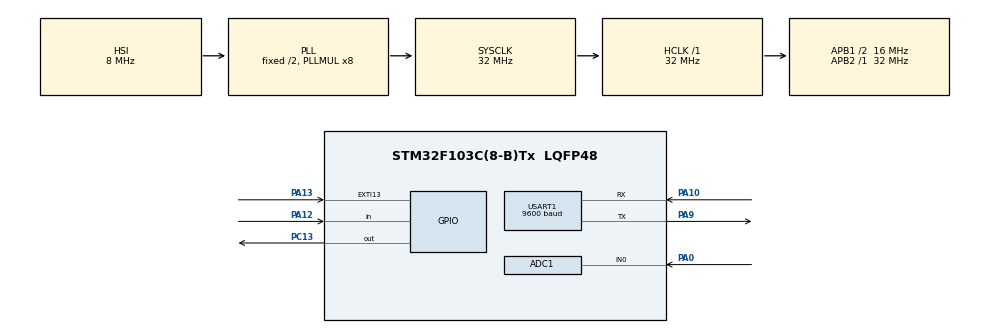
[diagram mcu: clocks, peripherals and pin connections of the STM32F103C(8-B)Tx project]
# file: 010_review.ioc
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ADC1.Channel-2\#ChannelRegularConversion=ADC_CHANNEL_0
ADC1.ContinuousConvMode=ENABLE
ADC1.NbrOfConversionFlag=1
ADC1.Rank-2\#ChannelRegularConversion=1
ADC1.SamplingTime-2\#ChannelRegularConversion=ADC_SAMPLETIME_1CYCLE_5
ADC1.master=1
Mcu.Family=STM32F1
Mcu.Name=STM32F103C(8-B)Tx
Mcu.Package=LQFP48
NVIC.EXTI15_10_IRQn=true\:0\:0\:false\:false\:true\:true\:true\:true
NVIC.PriorityGroup=NVIC_PRIORITYGROUP_4
NVIC.TIM2_IRQn=true\:0\:0\:false\:false\:true\:true\:true\:true
NVIC.USART1_IRQn=true\:0\:0\:false\:false\:true\:true\:true\:true
PA0-WKUP.Signal=ADCx_IN0
PA10.Mode=Asynchronous
PA10.Signal=USART1_RX
PA12.Signal=GPIO_Input
PA13.GPIO_ModeDefaultEXTI=GPIO_MODE_IT_FALLING
PA13.GPIO_PuPd=GPIO_PULLUP
PA13.Signal=GPXTI13
PA9.Mode=Asynchronous
PA9.Signal=USART1_TX
PC13-TAMPER-RTC.Signal=GPIO_Output
ProjectManager.HeapSize=0x200
ProjectManager.StackSize=0x400
ProjectManager.TargetToolchain=Makefile
RCC.ADCPresc=RCC_ADCPCLK2_DIV4
RCC.AHBFreq_Value=32000000
RCC.APB1CLKDivider=RCC_HCLK_DIV2
RCC.APB1Freq_Value=16000000
RCC.APB1TimFreq_Value=32000000
RCC.APB2Freq_Value=32000000
RCC.APB2TimFreq_Value=32000000
RCC.HCLKFreq_Value=32000000
RCC.PLLMUL=RCC_PLL_MUL8
RCC.SYSCLKFreq_VALUE=32000000
RCC.SYSCLKSource=RCC_SYSCLKSOURCE_PLLCLK
RCC.USBFreq_Value=32000000
SH.ADCx_IN0.0=ADC1_IN0,IN0
TIM2.Period=300
TIM2.Prescaler=31999
USART1.BaudRate=9600
USART1.VirtualMode=VM_ASYNC
VP_SYS_VS_ND.Mode=No_Debug
VP_TIM2_VS_ClockSourceINT.Mode=Internal
board=custom

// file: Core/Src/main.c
/* USER CODE BEGIN Header */
/**
 ******************************************************************************
 * @file           : main.c
 * @brief          : Main program body
 ******************************************************************************
 * @attention
 *
 * Copyright (c) 2024 STMicroelectronics.
 * All rights reserved.
 *
 * This software is licensed under terms that can be found in the LICENSE file
 * in the root directory of this software component.
 * If no LICENSE file comes with this software, it is provided AS-IS.
 *
 ******************************************************************************
 */
/* USER CODE END Header */
#include "main.h"
#include "adc.h"
#include "tim.h"
#include "usart.h"
#include "gpio.h"

void SystemClock_Config(void);

int main(void)
{

  /* MCU Configuration--------------------------------------------------------*/

  /* Reset of all peripherals, Initializes the Flash interface and the Systick. */
  HAL_Init();

  /* Configure the system clock */
  SystemClock_Config();

  /* Initialize all configured peripherals */
  MX_GPIO_Init();
  MX_TIM2_Init();
  MX_USART1_UART_Init();
  MX_ADC1_Init();
  /* USER CODE BEGIN 2 */
  HAL_ADC_Start(&hadc1);
  /* USER CODE END 2 */

  /* Infinite loop */
  /* USER CODE BEGIN WHILE */

  uint32_t adc_buff;

  while (1)
  {
    if (!HAL_ADC_PollForConversion(&hadc1, 100))
    {
      adc_buff = HAL_ADC_GetValue(&hadc1);
    }
    /* USER CODE END WHILE */

  }
}

void SystemClock_Config(void)
{
  RCC_OscInitTypeDef RCC_OscInitStruct = {0};
  RCC_ClkInitTypeDef RCC_ClkInitStruct = {0};
  RCC_PeriphCLKInitTypeDef PeriphClkInit = {0};

  /** Initializes the RCC Oscillators according to the specified parameters
   * in the RCC_OscInitTypeDef structure.
   */
  RCC_OscInitStruct.OscillatorType = RCC_OSCILLATORTYPE_HSI;
  RCC_OscInitStruct.HSIState = RCC_HSI_ON;
  RCC_OscInitStruct.HSICalibrationValue = RCC_HSICALIBRATION_DEFAULT;
  RCC_OscInitStruct.PLL.PLLState = RCC_PLL_ON;
  RCC_OscInitStruct.PLL.PLLSource = RCC_PLLSOURCE_HSI_DIV2;
  RCC_OscInitStruct.PLL.PLLMUL = RCC_PLL_MUL8;
  if (HAL_RCC_OscConfig(&RCC_OscInitStruct) != HAL_OK)
  {
    Error_Handler();
  }

  /** Initializes the CPU, AHB and APB buses clocks
   */
  RCC_ClkInitStruct.ClockType = RCC_CLOCKTYPE_HCLK | RCC_CLOCKTYPE_SYSCLK | RCC_CLOCKTYPE_PCLK1 | RCC_CLOCKTYPE_PCLK2;
  RCC_ClkInitStruct.SYSCLKSource = RCC_SYSCLKSOURCE_PLLCLK;
  RCC_ClkInitStruct.AHBCLKDivider = RCC_SYSCLK_DIV1;
  RCC_ClkInitStruct.APB1CLKDivider = RCC_HCLK_DIV2;
  RCC_ClkInitStruct.APB2CLKDivider = RCC_HCLK_DIV1;

  if (HAL_RCC_ClockConfig(&RCC_ClkInitStruct, FLASH_LATENCY_1) != HAL_OK)
  {
    Error_Handler();
  }
  PeriphClkInit.PeriphClockSelection = RCC_PERIPHCLK_ADC;
  PeriphClkInit.AdcClockSelection = RCC_ADCPCLK2_DIV4;
  if (HAL_RCCEx_PeriphCLKConfig(&PeriphClkInit) != HAL_OK)
  {
    Error_Handler();
  }
}

void Error_Handler(void)
{
  __disable_irq();
  while (1)
  {
  }
}
